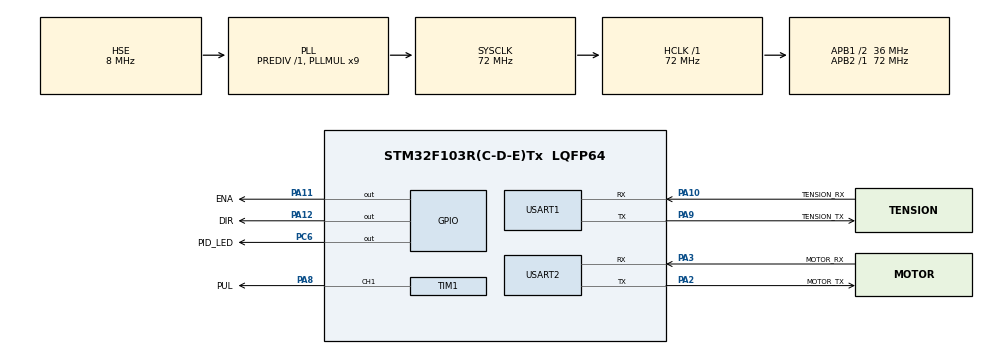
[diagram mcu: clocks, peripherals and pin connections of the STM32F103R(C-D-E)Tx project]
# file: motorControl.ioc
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Mcu.Family=STM32F1
Mcu.Name=STM32F103R(C-D-E)Tx
Mcu.Package=LQFP64
NVIC.PriorityGroup=NVIC_PRIORITYGROUP_4
NVIC.TIM2_IRQn=true\:1\:0\:true\:false\:true\:true\:true\:true
NVIC.USART1_IRQn=true\:0\:0\:true\:false\:true\:true\:true\:true
PA10.GPIO_Label=TENSION_RX
PA10.Mode=Asynchronous
PA10.Signal=USART1_RX
PA11.GPIO_Label=ENA
PA11.GPIO_PuPd=GPIO_PULLUP
PA11.Signal=GPIO_Output
PA12.GPIO_Label=DIR
PA12.GPIO_PuPd=GPIO_PULLUP
PA12.Signal=GPIO_Output
PA13.Mode=Serial_Wire
PA13.Signal=SYS_JTMS-SWDIO
PA14.Mode=Serial_Wire
PA14.Signal=SYS_JTCK-SWCLK
PA2.GPIO_Label=MOTOR_TX
PA2.Mode=Asynchronous
PA2.Signal=USART2_TX
PA3.GPIO_Label=MOTOR_RX
PA3.Mode=Asynchronous
PA3.Signal=USART2_RX
PA8.GPIO_Label=PUL
PA8.Signal=S_TIM1_CH1
PA9.GPIO_Label=TENSION_TX
PA9.Mode=Asynchronous
PA9.Signal=USART1_TX
PC14-OSC32_IN.Mode=LSE-External-Oscillator
PC14-OSC32_IN.Signal=RCC_OSC32_IN
PC15-OSC32_OUT.Mode=LSE-External-Oscillator
PC15-OSC32_OUT.Signal=RCC_OSC32_OUT
PC6.GPIO_Label=PID_LED
PC6.GPIO_PuPd=GPIO_PULLDOWN
PC6.Signal=GPIO_Output
PD0-OSC_IN.Mode=HSE-External-Oscillator
PD0-OSC_IN.Signal=RCC_OSC_IN
PD1-OSC_OUT.Mode=HSE-External-Oscillator
PD1-OSC_OUT.Signal=RCC_OSC_OUT
ProjectManager.HeapSize=0x200
ProjectManager.StackSize=0x400
ProjectManager.TargetToolchain=MDK-ARM V5.32
RCC.AHBFreq_Value=72000000
RCC.APB1CLKDivider=RCC_HCLK_DIV2
RCC.APB1Freq_Value=36000000
RCC.APB1TimFreq_Value=72000000
RCC.APB2Freq_Value=72000000
RCC.APB2TimFreq_Value=72000000
RCC.HCLKFreq_Value=72000000
RCC.PLLMUL=RCC_PLL_MUL9
RCC.PLLSourceVirtual=RCC_PLLSOURCE_HSE
RCC.SYSCLKFreq_VALUE=72000000
RCC.SYSCLKSource=RCC_SYSCLKSOURCE_PLLCLK
RCC.USBFreq_Value=72000000
SH.S_TIM1_CH1.0=TIM1_CH1,PWM Generation1 CH1
TIM1.AutoReloadPreload=TIM_AUTORELOAD_PRELOAD_ENABLE
TIM1.Channel-PWM\ Generation1\ CH1=TIM_CHANNEL_1
TIM1.Period=100-1
TIM1.Prescaler=720-1
TIM1.Pulse-PWM\ Generation1\ CH1=50
TIM2.AutoReloadPreload=TIM_AUTORELOAD_PRELOAD_ENABLE
TIM2.Period=1000-1
TIM2.Prescaler=72-1
USART1.VirtualMode=VM_ASYNC
USART2.VirtualMode=VM_ASYNC
VP_TIM1_VS_ClockSourceINT.Mode=Internal
VP_TIM2_VS_ClockSourceINT.Mode=Internal
board=custom

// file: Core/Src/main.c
/* USER CODE BEGIN Header */
/**
  ******************************************************************************
  * @file           : main.c
  * @brief          : Main program body
  ******************************************************************************
  * @attention
  *
  * Copyright (c) 2026 STMicroelectronics.
  * All rights reserved.
  *
  * This software is licensed under terms that can be found in the LICENSE file
  * in the root directory of this software component.
  * If no LICENSE file comes with this software, it is provided AS-IS.
  *
  ******************************************************************************
  */
/* USER CODE END Header */
#include "main.h"

TIM_HandleTypeDef htim1;
TIM_HandleTypeDef htim2;

UART_HandleTypeDef huart1;
UART_HandleTypeDef huart2;

void SystemClock_Config(void);
static void MX_GPIO_Init(void);
static void MX_TIM1_Init(void);
static void MX_USART1_UART_Init(void);
static void MX_USART2_UART_Init(void);
static void MX_TIM2_Init(void);

int main(void)
{

  /* MCU Configuration--------------------------------------------------------*/

  /* Reset of all peripherals, Initializes the Flash interface and the Systick. */
  HAL_Init();

  /* Configure the system clock */
  SystemClock_Config();

  /* Initialize all configured peripherals */
  MX_GPIO_Init();
  MX_TIM1_Init();
  MX_USART1_UART_Init();
  MX_USART2_UART_Init();
  MX_TIM2_Init();
  /* USER CODE BEGIN 2 */
  // 启动定时器1的PWM模式，通道1
  HAL_TIM_PWM_Start(&htim1, TIM_CHANNEL_1);
  // 启动定时器2,用于判定并计算pid
  HAL_TIM_Base_Start_IT(&htim2);
  // 启动USART1的接收中断
  extern volatile char usart1_rx_byte; // 声明外部变量
  HAL_UART_Receive_IT(&huart1, (uint8_t *)&usart1_rx_byte, 1);
  // 初始化转速
  control(0.0f);
  /* USER CODE END 2 */

  /* Infinite loop */
  while (1)
  {

  }
}

void SystemClock_Config(void)
{
  RCC_OscInitTypeDef RCC_OscInitStruct = {0};
  RCC_ClkInitTypeDef RCC_ClkInitStruct = {0};

  /** Initializes the RCC Oscillators according to the specified parameters
  * in the RCC_OscInitTypeDef structure.
  */
  RCC_OscInitStruct.OscillatorType = RCC_OSCILLATORTYPE_HSE;
  RCC_OscInitStruct.HSEState = RCC_HSE_ON;
  RCC_OscInitStruct.HSEPredivValue = RCC_HSE_PREDIV_DIV1;
  RCC_OscInitStruct.HSIState = RCC_HSI_ON;
  RCC_OscInitStruct.PLL.PLLState = RCC_PLL_ON;
  RCC_OscInitStruct.PLL.PLLSource = RCC_PLLSOURCE_HSE;
  RCC_OscInitStruct.PLL.PLLMUL = RCC_PLL_MUL9;
  if (HAL_RCC_OscConfig(&RCC_OscInitStruct) != HAL_OK)
  {
    Error_Handler();
  }

  /** Initializes the CPU, AHB and APB buses clocks
  */
  RCC_ClkInitStruct.ClockType = RCC_CLOCKTYPE_HCLK|RCC_CLOCKTYPE_SYSCLK
                              |RCC_CLOCKTYPE_PCLK1|RCC_CLOCKTYPE_PCLK2;
  RCC_ClkInitStruct.SYSCLKSource = RCC_SYSCLKSOURCE_PLLCLK;
  RCC_ClkInitStruct.AHBCLKDivider = RCC_SYSCLK_DIV1;
  RCC_ClkInitStruct.APB1CLKDivider = RCC_HCLK_DIV2;
  RCC_ClkInitStruct.APB2CLKDivider = RCC_HCLK_DIV1;

  if (HAL_RCC_ClockConfig(&RCC_ClkInitStruct, FLASH_LATENCY_2) != HAL_OK)
  {
    Error_Handler();
  }
}

static void MX_TIM1_Init(void)
{

  TIM_ClockConfigTypeDef sClockSourceConfig = {0};
  TIM_MasterConfigTypeDef sMasterConfig = {0};
  TIM_OC_InitTypeDef sConfigOC = {0};
  TIM_BreakDeadTimeConfigTypeDef sBreakDeadTimeConfig = {0};

  htim1.Instance = TIM1;
  htim1.Init.Prescaler = 720-1;
  htim1.Init.CounterMode = TIM_COUNTERMODE_UP;
  htim1.Init.Period = 100-1;
  htim1.Init.ClockDivision = TIM_CLOCKDIVISION_DIV1;
  htim1.Init.RepetitionCounter = 0;
  htim1.Init.AutoReloadPreload = TIM_AUTORELOAD_PRELOAD_ENABLE;
  if (HAL_TIM_Base_Init(&htim1) != HAL_OK)
  {
    Error_Handler();
  }
  sClockSourceConfig.ClockSource = TIM_CLOCKSOURCE_INTERNAL;
  if (HAL_TIM_ConfigClockSource(&htim1, &sClockSourceConfig) != HAL_OK)
  {
    Error_Handler();
  }
  if (HAL_TIM_PWM_Init(&htim1) != HAL_OK)
  {
    Error_Handler();
  }
  sMasterConfig.MasterOutputTrigger = TIM_TRGO_RESET;
  sMasterConfig.MasterSlaveMode = TIM_MASTERSLAVEMODE_DISABLE;
  if (HAL_TIMEx_MasterConfigSynchronization(&htim1, &sMasterConfig) != HAL_OK)
  {
    Error_Handler();
  }
  sConfigOC.OCMode = TIM_OCMODE_PWM1;
  sConfigOC.Pulse = 50;
  sConfigOC.OCPolarity = TIM_OCPOLARITY_HIGH;
  sConfigOC.OCNPolarity = TIM_OCNPOLARITY_HIGH;
  sConfigOC.OCFastMode = TIM_OCFAST_DISABLE;
  sConfigOC.OCIdleState = TIM_OCIDLESTATE_RESET;
  sConfigOC.OCNIdleState = TIM_OCNIDLESTATE_RESET;
  if (HAL_TIM_PWM_ConfigChannel(&htim1, &sConfigOC, TIM_CHANNEL_1) != HAL_OK)
  {
    Error_Handler();
  }
  sBreakDeadTimeConfig.OffStateRunMode = TIM_OSSR_DISABLE;
  sBreakDeadTimeConfig.OffStateIDLEMode = TIM_OSSI_DISABLE;
  sBreakDeadTimeConfig.LockLevel = TIM_LOCKLEVEL_OFF;
  sBreakDeadTimeConfig.DeadTime = 0;
  sBreakDeadTimeConfig.BreakState = TIM_BREAK_DISABLE;
  sBreakDeadTimeConfig.BreakPolarity = TIM_BREAKPOLARITY_HIGH;
  sBreakDeadTimeConfig.AutomaticOutput = TIM_AUTOMATICOUTPUT_DISABLE;
  if (HAL_TIMEx_ConfigBreakDeadTime(&htim1, &sBreakDeadTimeConfig) != HAL_OK)
  {
    Error_Handler();
  }
  HAL_TIM_MspPostInit(&htim1);

}

static void MX_TIM2_Init(void)
{

  TIM_ClockConfigTypeDef sClockSourceConfig = {0};
  TIM_MasterConfigTypeDef sMasterConfig = {0};

  htim2.Instance = TIM2;
  htim2.Init.Prescaler = 72-1;
  htim2.Init.CounterMode = TIM_COUNTERMODE_UP;
  htim2.Init.Period = 1000-1;
  htim2.Init.ClockDivision = TIM_CLOCKDIVISION_DIV1;
  htim2.Init.AutoReloadPreload = TIM_AUTORELOAD_PRELOAD_ENABLE;
  if (HAL_TIM_Base_Init(&htim2) != HAL_OK)
  {
    Error_Handler();
  }
  sClockSourceConfig.ClockSource = TIM_CLOCKSOURCE_INTERNAL;
  if (HAL_TIM_ConfigClockSource(&htim2, &sClockSourceConfig) != HAL_OK)
  {
    Error_Handler();
  }
  sMasterConfig.MasterOutputTrigger = TIM_TRGO_RESET;
  sMasterConfig.MasterSlaveMode = TIM_MASTERSLAVEMODE_DISABLE;
  if (HAL_TIMEx_MasterConfigSynchronization(&htim2, &sMasterConfig) != HAL_OK)
  {
    Error_Handler();
  }

}

static void MX_USART1_UART_Init(void)
{

  huart1.Instance = USART1;
  huart1.Init.BaudRate = 115200;
  huart1.Init.WordLength = UART_WORDLENGTH_8B;
  huart1.Init.StopBits = UART_STOPBITS_1;
  huart1.Init.Parity = UART_PARITY_NONE;
  huart1.Init.Mode = UART_MODE_TX_RX;
  huart1.Init.HwFlowCtl = UART_HWCONTROL_NONE;
  huart1.Init.OverSampling = UART_OVERSAMPLING_16;
  if (HAL_UART_Init(&huart1) != HAL_OK)
  {
    Error_Handler();
  }

}

static void MX_USART2_UART_Init(void)
{

  huart2.Instance = USART2;
  huart2.Init.BaudRate = 115200;
  huart2.Init.WordLength = UART_WORDLENGTH_8B;
  huart2.Init.StopBits = UART_STOPBITS_1;
  huart2.Init.Parity = UART_PARITY_NONE;
  huart2.Init.Mode = UART_MODE_TX_RX;
  huart2.Init.HwFlowCtl = UART_HWCONTROL_NONE;
  huart2.Init.OverSampling = UART_OVERSAMPLING_16;
  if (HAL_UART_Init(&huart2) != HAL_OK)
  {
    Error_Handler();
  }

}

static void MX_GPIO_Init(void)
{
  GPIO_InitTypeDef GPIO_InitStruct = {0};

  /* GPIO Ports Clock Enable */
  __HAL_RCC_GPIOC_CLK_ENABLE();
  __HAL_RCC_GPIOD_CLK_ENABLE();
  __HAL_RCC_GPIOA_CLK_ENABLE();

  /*Configure GPIO pin Output Level */
  HAL_GPIO_WritePin(PID_LED_GPIO_Port, PID_LED_Pin, GPIO_PIN_RESET);

  /*Configure GPIO pin Output Level */
  HAL_GPIO_WritePin(GPIOA, ENA_Pin|DIR_Pin, GPIO_PIN_RESET);

  /*Configure GPIO pin : PID_LED_Pin */
  GPIO_InitStruct.Pin = PID_LED_Pin;
  GPIO_InitStruct.Mode = GPIO_MODE_OUTPUT_PP;
  GPIO_InitStruct.Pull = GPIO_PULLDOWN;
  GPIO_InitStruct.Speed = GPIO_SPEED_FREQ_LOW;
  HAL_GPIO_Init(PID_LED_GPIO_Port, &GPIO_InitStruct);

  /*Configure GPIO pins : ENA_Pin DIR_Pin */
  GPIO_InitStruct.Pin = ENA_Pin|DIR_Pin;
  GPIO_InitStruct.Mode = GPIO_MODE_OUTPUT_PP;
  GPIO_InitStruct.Pull = GPIO_PULLUP;
  GPIO_InitStruct.Speed = GPIO_SPEED_FREQ_LOW;
  HAL_GPIO_Init(GPIOA, &GPIO_InitStruct);

}

void Error_Handler(void)
{
  __disable_irq();
  while (1)
  {
  }
}
